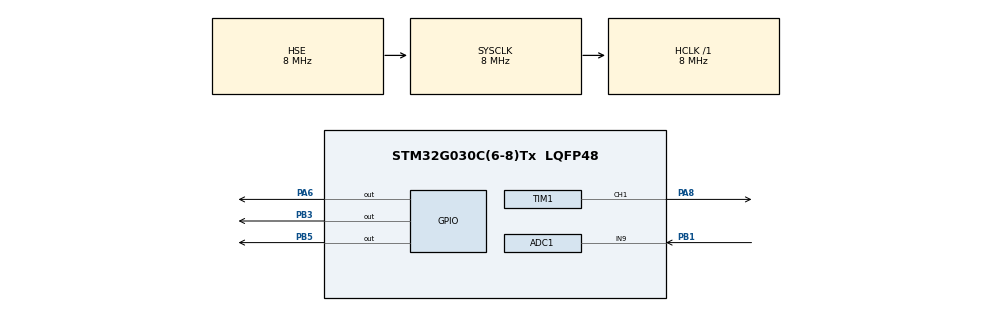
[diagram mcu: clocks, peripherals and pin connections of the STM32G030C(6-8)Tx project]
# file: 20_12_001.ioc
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ADC1.Channel-4\#ChannelRegularConversion=ADC_CHANNEL_9
ADC1.ContinuousConvMode=ENABLE
ADC1.DMAContinuousRequests=ENABLE
ADC1.NbrOfConversionFlag=1
ADC1.Overrun=ADC_OVR_DATA_OVERWRITTEN
ADC1.Rank-4\#ChannelRegularConversion=1
ADC1.SamplingTime-4\#ChannelRegularConversion=ADC_SAMPLINGTIME_COMMON_1
ADC1.SamplingTimeCommon1=ADC_SAMPLETIME_160CYCLES_5
ADC1.SamplingTimeCommon2=ADC_SAMPLETIME_12CYCLES_5
ADC1.SelectedChannel=ADC_CHANNEL_9
ADC1.master=1
Dma.ADC1.0.Direction=DMA_PERIPH_TO_MEMORY
Dma.ADC1.0.EventEnable=DISABLE
Dma.ADC1.0.Instance=DMA1_Channel1
Dma.ADC1.0.MemDataAlignment=DMA_MDATAALIGN_WORD
Dma.ADC1.0.MemInc=DMA_MINC_ENABLE
Dma.ADC1.0.Mode=DMA_CIRCULAR
Dma.ADC1.0.PeriphDataAlignment=DMA_PDATAALIGN_WORD
Dma.ADC1.0.PeriphInc=DMA_PINC_DISABLE
Dma.ADC1.0.Polarity=HAL_DMAMUX_REQ_GEN_RISING
Dma.ADC1.0.Priority=DMA_PRIORITY_LOW
Dma.ADC1.0.RequestNumber=1
Dma.ADC1.0.SignalID=NONE
Dma.ADC1.0.SyncEnable=DISABLE
Dma.ADC1.0.SyncPolarity=HAL_DMAMUX_SYNC_NO_EVENT
Dma.ADC1.0.SyncRequestNumber=1
Dma.ADC1.0.SyncSignalID=NONE
Dma.Request0=ADC1
Mcu.Family=STM32G0
Mcu.Name=STM32G030C(6-8)Tx
Mcu.Package=LQFP48
NVIC.TIM14_IRQn=true\:0\:0\:false\:false\:true\:true\:true\:true
PA13.Mode=Serial_Wire
PA13.Signal=SYS_SWDIO
PA14-BOOT0.Mode=Serial_Wire
PA14-BOOT0.Signal=SYS_SWCLK
PA6.Signal=GPIO_Output
PA8.Signal=S_TIM1_CH1
PB1.Mode=IN9
PB1.Signal=ADC1_IN9
PB3.Signal=GPIO_Output
PB5.Signal=GPIO_Output
PF0-OSC_IN\ (PF0).Mode=HSE-External-Oscillator
PF0-OSC_IN\ (PF0).Signal=RCC_OSC_IN
PF1-OSC_OUT\ (PF1).Mode=HSE-External-Oscillator
PF1-OSC_OUT\ (PF1).Signal=RCC_OSC_OUT
ProjectManager.HeapSize=0x200
ProjectManager.StackSize=0x400
ProjectManager.TargetToolchain=STM32CubeIDE
RCC.ADCFreq_Value=8000000
RCC.AHBFreq_Value=8000000
RCC.CortexFreq_Value=8000000
RCC.EXTERNAL_CLOCK_VALUE=12288000
RCC.HCLKFreq_Value=8000000
RCC.HSE_VALUE=8000000
RCC.HSISYSCLKDivider=RCC_HSI_DIV2
RCC.HSI_VALUE=16000000
RCC.LSE_VALUE=32768
RCC.PLLR=RCC_PLLR_DIV8
RCC.SYSCLKFreq_VALUE=8000000
RCC.SYSCLKSource=RCC_SYSCLKSOURCE_HSE
RCC.VCOOutputFreq_Value=128000000
SH.S_TIM1_CH1.0=TIM1_CH1,PWM Generation1 CH1
TIM1.AutoReloadPreload=TIM_AUTORELOAD_PRELOAD_ENABLE
TIM1.Channel-PWM\ Generation1\ CH1=TIM_CHANNEL_1
TIM1.OCFastMode_PWM-PWM\ Generation1\ CH1=TIM_OCFAST_DISABLE
TIM1.Period=999
TIM1.Prescaler=7
TIM1.Pulse-PWM\ Generation1\ CH1=0
TIM14.Period=999
TIM14.Prescaler=799
VP_TIM14_VS_ClockSourceINT.Mode=Enable_Timer
board=custom

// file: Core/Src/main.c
/* USER CODE BEGIN Header */
/**
  ******************************************************************************
  * @file    main.c
  * @author  vkusnuiplov
  * @brief   Main program file
  *
  * @details This file is responsible for low-level MCU initialization, binding
  * abstraction layers, and starting the infinite processing loop.
  ******************************************************************************
  * @section Project Architecture Overview
  *
  * The project is organized in a multi-layered structure to isolate hardware:
  *
  * 1. Application Layer (/application)
  * High-level logic, FSM defines device states
  *
  * 2. Drivers Layer (/actuators, /sensor)
  * Hardware-independent peripheral drivers (LED, Buzzer, MQ7)
  *
  * 3. BSP Layer (/bsp)
  * Board Support Package. The file that links drivers and STM32 HAL
  *
  * 4. HAL
  * Low-level code generated by STM32CubeIDE
  *
  ******************************************************************************
  * @section Naming Convention Style Guide
  *
  * _t  [Type]     : Structure type declarations
  * _e  [Enum]     : Enumeration types for states and modes
  * _h  [Handle]   : Specific instance of an object in memory
  * _hw [Hardware] : Internal functions for direct hardware interaction
  *
  ******************************************************************************
  * @section System Execution Flow
  *
  * 1. Reset & Clock Cleanup -> Core clock configuration
  * 2. Peripheral Init       -> GPIO, ADC+DMA, TIM_PWM configuration
  * 3. Application Init      -> Calling app_init(), binding BSP with drivers
  * 4. Infinite Loop         -> Calling app_process() ->
  * -> [ Sensors Update ] -> [ FSM Logic Check ] -> [ Actuators Refresh ]
  *
  ******************************************************************************
  */
/* USER CODE END Header */
#include "main.h"

/* USER CODE BEGIN Includes */
#include "application.h"
/* USER CODE END Includes */

ADC_HandleTypeDef hadc1;
DMA_HandleTypeDef hdma_adc1;

TIM_HandleTypeDef htim1;
TIM_HandleTypeDef htim14;

/* USER CODE BEGIN PV */
application_t h_app;
/* USER CODE END PV */

void SystemClock_Config(void);
static void MX_GPIO_Init(void);
static void MX_DMA_Init(void);
static void MX_ADC1_Init(void);
static void MX_TIM14_Init(void);
static void MX_TIM1_Init(void);

int main(void)
{

  /* MCU Configuration--------------------------------------------------------*/

  /* Reset of all peripherals, Initializes the Flash interface and the Systick. */
  HAL_Init();

  /* Configure the system clock */
  SystemClock_Config();

  /* Initialize all configured peripherals */
  MX_GPIO_Init();
  MX_DMA_Init();
  MX_ADC1_Init();
  MX_TIM14_Init();
  MX_TIM1_Init();
  /* USER CODE BEGIN 2 */
  app_init(&h_app);
  /* USER CODE END 2 */

  /* Infinite loop */
  /* USER CODE BEGIN WHILE */
  while (1)
  {
	  app_process(&h_app, HAL_GetTick());
    /* USER CODE END WHILE */

  }
}

void SystemClock_Config(void)
{
  RCC_OscInitTypeDef RCC_OscInitStruct = {0};
  RCC_ClkInitTypeDef RCC_ClkInitStruct = {0};

  /** Configure the main internal regulator output voltage
  */
  HAL_PWREx_ControlVoltageScaling(PWR_REGULATOR_VOLTAGE_SCALE1);

  /** Initializes the RCC Oscillators according to the specified parameters
  * in the RCC_OscInitTypeDef structure.
  */
  RCC_OscInitStruct.OscillatorType = RCC_OSCILLATORTYPE_HSE;
  RCC_OscInitStruct.HSEState = RCC_HSE_ON;
  RCC_OscInitStruct.PLL.PLLState = RCC_PLL_NONE;
  if (HAL_RCC_OscConfig(&RCC_OscInitStruct) != HAL_OK)
  {
    Error_Handler();
  }

  /** Initializes the CPU, AHB and APB buses clocks
  */
  RCC_ClkInitStruct.ClockType = RCC_CLOCKTYPE_HCLK|RCC_CLOCKTYPE_SYSCLK
                              |RCC_CLOCKTYPE_PCLK1;
  RCC_ClkInitStruct.SYSCLKSource = RCC_SYSCLKSOURCE_HSE;
  RCC_ClkInitStruct.AHBCLKDivider = RCC_SYSCLK_DIV1;
  RCC_ClkInitStruct.APB1CLKDivider = RCC_HCLK_DIV1;

  if (HAL_RCC_ClockConfig(&RCC_ClkInitStruct, FLASH_LATENCY_0) != HAL_OK)
  {
    Error_Handler();
  }
}

static void MX_ADC1_Init(void)
{

  ADC_ChannelConfTypeDef sConfig = {0};

  /** Configure the global features of the ADC (Clock, Resolution, Data Alignment and number of conversion)
  */
  hadc1.Instance = ADC1;
  hadc1.Init.ClockPrescaler = ADC_CLOCK_SYNC_PCLK_DIV1;
  hadc1.Init.Resolution = ADC_RESOLUTION_12B;
  hadc1.Init.DataAlign = ADC_DATAALIGN_RIGHT;
  hadc1.Init.ScanConvMode = ADC_SCAN_DISABLE;
  hadc1.Init.EOCSelection = ADC_EOC_SINGLE_CONV;
  hadc1.Init.LowPowerAutoWait = DISABLE;
  hadc1.Init.LowPowerAutoPowerOff = DISABLE;
  hadc1.Init.ContinuousConvMode = ENABLE;
  hadc1.Init.NbrOfConversion = 1;
  hadc1.Init.ExternalTrigConv = ADC_SOFTWARE_START;
  hadc1.Init.ExternalTrigConvEdge = ADC_EXTERNALTRIGCONVEDGE_NONE;
  hadc1.Init.DMAContinuousRequests = ENABLE;
  hadc1.Init.Overrun = ADC_OVR_DATA_OVERWRITTEN;
  hadc1.Init.SamplingTimeCommon1 = ADC_SAMPLETIME_160CYCLES_5;
  hadc1.Init.SamplingTimeCommon2 = ADC_SAMPLETIME_12CYCLES_5;
  hadc1.Init.OversamplingMode = DISABLE;
  hadc1.Init.TriggerFrequencyMode = ADC_TRIGGER_FREQ_HIGH;
  if (HAL_ADC_Init(&hadc1) != HAL_OK)
  {
    Error_Handler();
  }

  /** Configure Regular Channel
  */
  sConfig.Channel = ADC_CHANNEL_9;
  sConfig.Rank = ADC_REGULAR_RANK_1;
  sConfig.SamplingTime = ADC_SAMPLINGTIME_COMMON_1;
  if (HAL_ADC_ConfigChannel(&hadc1, &sConfig) != HAL_OK)
  {
    Error_Handler();
  }

}

static void MX_TIM1_Init(void)
{

  TIM_MasterConfigTypeDef sMasterConfig = {0};
  TIM_OC_InitTypeDef sConfigOC = {0};
  TIM_BreakDeadTimeConfigTypeDef sBreakDeadTimeConfig = {0};

  htim1.Instance = TIM1;
  htim1.Init.Prescaler = 7;
  htim1.Init.CounterMode = TIM_COUNTERMODE_UP;
  htim1.Init.Period = 999;
  htim1.Init.ClockDivision = TIM_CLOCKDIVISION_DIV1;
  htim1.Init.RepetitionCounter = 0;
  htim1.Init.AutoReloadPreload = TIM_AUTORELOAD_PRELOAD_ENABLE;
  if (HAL_TIM_PWM_Init(&htim1) != HAL_OK)
  {
    Error_Handler();
  }
  sMasterConfig.MasterOutputTrigger = TIM_TRGO_RESET;
  sMasterConfig.MasterOutputTrigger2 = TIM_TRGO2_RESET;
  sMasterConfig.MasterSlaveMode = TIM_MASTERSLAVEMODE_DISABLE;
  if (HAL_TIMEx_MasterConfigSynchronization(&htim1, &sMasterConfig) != HAL_OK)
  {
    Error_Handler();
  }
  sConfigOC.OCMode = TIM_OCMODE_PWM1;
  sConfigOC.Pulse = 0;
  sConfigOC.OCPolarity = TIM_OCPOLARITY_HIGH;
  sConfigOC.OCNPolarity = TIM_OCNPOLARITY_HIGH;
  sConfigOC.OCFastMode = TIM_OCFAST_DISABLE;
  sConfigOC.OCIdleState = TIM_OCIDLESTATE_RESET;
  sConfigOC.OCNIdleState = TIM_OCNIDLESTATE_RESET;
  if (HAL_TIM_PWM_ConfigChannel(&htim1, &sConfigOC, TIM_CHANNEL_1) != HAL_OK)
  {
    Error_Handler();
  }
  sBreakDeadTimeConfig.OffStateRunMode = TIM_OSSR_DISABLE;
  sBreakDeadTimeConfig.OffStateIDLEMode = TIM_OSSI_DISABLE;
  sBreakDeadTimeConfig.LockLevel = TIM_LOCKLEVEL_OFF;
  sBreakDeadTimeConfig.DeadTime = 0;
  sBreakDeadTimeConfig.BreakState = TIM_BREAK_DISABLE;
  sBreakDeadTimeConfig.BreakPolarity = TIM_BREAKPOLARITY_HIGH;
  sBreakDeadTimeConfig.BreakFilter = 0;
  sBreakDeadTimeConfig.BreakAFMode = TIM_BREAK_AFMODE_INPUT;
  sBreakDeadTimeConfig.Break2State = TIM_BREAK2_DISABLE;
  sBreakDeadTimeConfig.Break2Polarity = TIM_BREAK2POLARITY_HIGH;
  sBreakDeadTimeConfig.Break2Filter = 0;
  sBreakDeadTimeConfig.Break2AFMode = TIM_BREAK_AFMODE_INPUT;
  sBreakDeadTimeConfig.AutomaticOutput = TIM_AUTOMATICOUTPUT_DISABLE;
  if (HAL_TIMEx_ConfigBreakDeadTime(&htim1, &sBreakDeadTimeConfig) != HAL_OK)
  {
    Error_Handler();
  }
  HAL_TIM_MspPostInit(&htim1);

}

static void MX_TIM14_Init(void)
{

  htim14.Instance = TIM14;
  htim14.Init.Prescaler = 799;
  htim14.Init.CounterMode = TIM_COUNTERMODE_UP;
  htim14.Init.Period = 999;
  htim14.Init.ClockDivision = TIM_CLOCKDIVISION_DIV1;
  htim14.Init.AutoReloadPreload = TIM_AUTORELOAD_PRELOAD_DISABLE;
  if (HAL_TIM_Base_Init(&htim14) != HAL_OK)
  {
    Error_Handler();
  }

}

static void MX_DMA_Init(void)
{

  /* DMA controller clock enable */
  __HAL_RCC_DMA1_CLK_ENABLE();

}

static void MX_GPIO_Init(void)
{
  GPIO_InitTypeDef GPIO_InitStruct = {0};

  /* GPIO Ports Clock Enable */
  __HAL_RCC_GPIOF_CLK_ENABLE();
  __HAL_RCC_GPIOA_CLK_ENABLE();
  __HAL_RCC_GPIOB_CLK_ENABLE();

  /*Configure GPIO pin Output Level */
  HAL_GPIO_WritePin(GPIOA, GPIO_PIN_6, GPIO_PIN_RESET);

  /*Configure GPIO pin Output Level */
  HAL_GPIO_WritePin(GPIOB, GPIO_PIN_3|GPIO_PIN_5, GPIO_PIN_RESET);

  /*Configure GPIO pin : PA6 */
  GPIO_InitStruct.Pin = GPIO_PIN_6;
  GPIO_InitStruct.Mode = GPIO_MODE_OUTPUT_PP;
  GPIO_InitStruct.Pull = GPIO_NOPULL;
  GPIO_InitStruct.Speed = GPIO_SPEED_FREQ_LOW;
  HAL_GPIO_Init(GPIOA, &GPIO_InitStruct);

  /*Configure GPIO pins : PB3 PB5 */
  GPIO_InitStruct.Pin = GPIO_PIN_3|GPIO_PIN_5;
  GPIO_InitStruct.Mode = GPIO_MODE_OUTPUT_PP;
  GPIO_InitStruct.Pull = GPIO_NOPULL;
  GPIO_InitStruct.Speed = GPIO_SPEED_FREQ_LOW;
  HAL_GPIO_Init(GPIOB, &GPIO_InitStruct);

}

/* USER CODE BEGIN 4 */
// --- ТУТ Я ВИДАЛИВ СТАРІ КОЛБЕКИ, ВОНИ БІЛЬШЕ НЕ ПОТРІБНІ ---
// Новий драйвер працює в while(1) через mq7_process
/* USER CODE END 4 */

void Error_Handler(void)
{
  __disable_irq();
  while (1)
  {
  }
}
